# rym32g1 register map
Vendor: Rainer Yutai Meng; Series: RYM32; File version: 1
CPU: CM3 r2p1, little endian, MPU, no FPU, 4 interrupt priority bits
Registers are 32-bit, read-write, no defined reset value unless marked. A register's access mark holds for its fields unless they carry their own. Offsets are from the block's base; [hi:lo] are bit positions; {n}, {i} and the like mark numbered series.

## UART1 — Universal Synchronous Receiver Transmitter 1
Base 0x40001000
Same registers: UART2 0x40011400
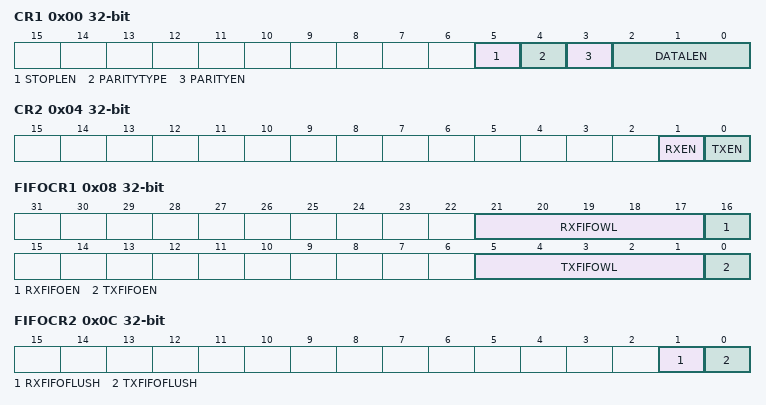
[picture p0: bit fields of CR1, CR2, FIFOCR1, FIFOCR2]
0x00 CR1 — UART1 Control Register 1
  [5] STOPLEN — UART1 CR1 STOPLEN Bit: Select stop bit(s) length
  [4] PARITYTYPE — UART1 CR1 PARITYTYPE Bit: Select parity type
  [3] PARITYEN — UART1 CR1 PARITYEN Bit: Enable / Disable parity bit
  [2:0] DATALEN — UART1 CR1 DATALEN [2:0] Bits: Select data bit(s) length
0x04 CR2 — UART1 Control Register 2
  [1] RXEN — UART1 CR2 RXEN Bit: Enable / Disable RX sub-system
  [0] TXEN — UART1 CR2 TXEN Bit: Enable / Disable TX sub-system
0x08 FIFOCR1 — UART1 FIFO Control Register 1
  [21:17] RXFIFOWL — UART1 FIFOCR1 RXFIFOWL [4:0] Bits: Select RXFIFO waterline
  [16] RXFIFOEN — UART1 FIFOCR1 RXFIFOEN Bit: Enable / Disable RXFIFO
  [5:1] TXFIFOWL — UART1 FIFOCR1 TXFIFOWL [4:0] Bits: Select TXFIFO waterline
  [0] TXFIFOEN — UART1 FIFOCR1 TXFIFOEN Bit: Enable / Disable TXFIFO
0x0C FIFOCR2 wo — UART1 FIFO Control Register 2
  [1] RXFIFOFLUSH — UART1 FIFOCR2 RXFIFOFLUSH Bit: Flush RXFIFO
  [0] TXFIFOFLUSH — UART1 FIFOCR2 TXFIFOFLUSH Bit: Flush TXFIFO
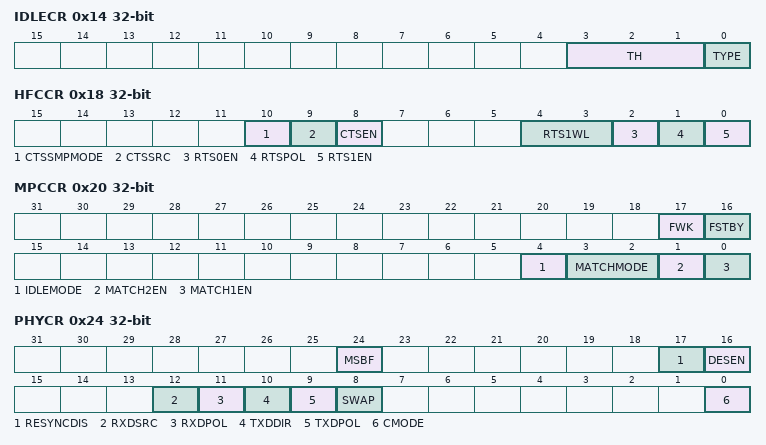
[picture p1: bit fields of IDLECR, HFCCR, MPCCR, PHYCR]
0x14 IDLECR — UART1 Idle Detection Control Register
  [3:1] TH — UART1 IDLECR TH [2:0] Bits: Select IDLE detection threshold
  [0] TYPE — UART1 IDLECR TYPE Bit: Select IDLE detection type
0x18 HFCCR — UART1 Hardware Flow Control Register
  [10] CTSSMPMODE — UART1 HFCCR CTSSMPMODE Bit: Select CTS sampling mode
  [9] CTSSRC — UART1 HFCCR CTSSRC Bit: Select CTS source (1 = align with RX standby state)
  [8] CTSEN — UART1 HFCCR CTSEN Bit: Enable / Disable CTS
  [4:3] RTS1WL — UART1 HFCCR RTS1WL [1:0] Bits: Select RTS mode1 (RX) waterline
  [2] RTS0EN — UART1 HFCCR RTS0EN Bit: Enable / Disable RTS mode0 (TX)
  [1] RTSPOL — UART1 HFCCR RTSPOL Bit: Select RTS polarity
  [0] RTS1EN — UART1 HFCCR RTS1EN Bit: Enable / Disable RTS mode1 (RX)
0x1C LINCR — UART1 LIN Control Register
  [0] BRKDETEN — UART1 LINCR BRKDETEN Bit: Enable / Disable LIN break Detection
0x20 MPCCR — UART1 Multi Processor Control Register
  [17] FWK wo — UART1 MPCCR FWK Bit: Force wake up
  [16] FSTBY wo — UART1 MPCCR FSTBY Bit: Force standby
  [4] IDLEMODE — UART1 MPCCR IDLEMODE Bit: Select IDLE flag setting on standby wakeup (MATCHMODE=00)
  [3:2] MATCHMODE — UART1 MPCCR MATCHMODE [1:0] Bits: Select match mode
  [1] MATCH2EN — UART1 MPCCR MATCH2EN Bit: Enable / Disable match buffer 2
  [0] MATCH1EN — UART1 MPCCR MATCH1EN Bit: Enable / Disable match buffer 1
0x24 PHYCR — UART1 Physical Layer Control Register
  [24] MSBF — UART1 PHYCR MSBF Bit: Enable / Disable most significant bit first mode
  [17] RESYNCDIS — UART1 PHYCR RESYNCDIS Bit: Disable / Enable resynchronization
  [16] DESEN — UART1 PHYCR DESEN Bit: Enable / Disable dual edge sampling mode
  [12] RXDSRC — UART1 PHYCR RXDSRC Bit: Select RXD source in un-full-duplex communication mode
  [11] RXDPOL — UART1 PHYCR RXDPOL Bit: Select RXD polarity
  [10] TXDDIR — UART1 PHYCR TXDDIR Bit: Select TXD direction in half-duplex mode
  [9] TXDPOL — UART1 PHYCR TXDPOL Bit: Select TXD polarity
  [8] SWAP — UART1 PHYCR SWAP Bit: Swap TXD / RXD
  [0] CMODE — UART1 PHYCR CMODE Bit: Enable / Disable un-full-duplex communication mode
0x40 BRR — UART1 Baud Rate Register
  [16:4] DIVMANT — UART1 BRR DIVMANT [12:0] Bits: Baud rate divider (mantissa)
0x44 OSRR — UART1 Oversampling Ratio Register
  [5:0] OSR — UART1 OSRR OSR [5:0] Bits: Oversampling ratio
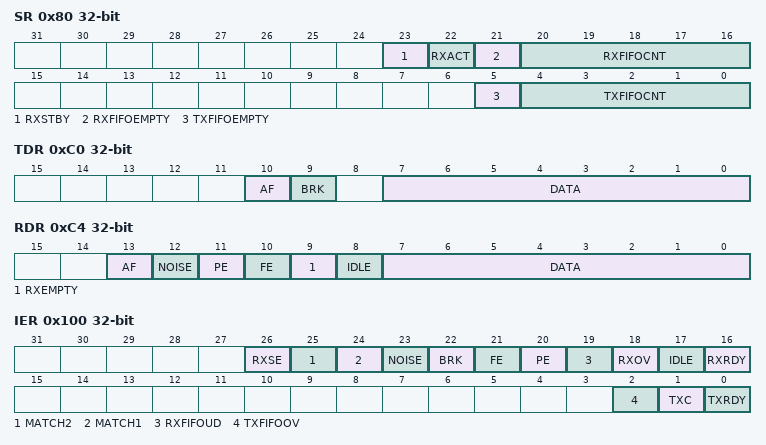
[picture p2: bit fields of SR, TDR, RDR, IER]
0x80 SR ro — UART1 Status Register
  [23] RXSTBY — UART1 SR RXSTBY Bit: RX standby
  [22] RXACT — UART1 SR RXACT Bit: RX active: valid start bit received (majority vote passed); holds until a full idle line is detected or RE=0
  [21] RXFIFOEMPTY — UART1 SR RXFIFOEMPTY Bit: RXFIFO empty
  [20:16] RXFIFOCNT — UART1 SR RXFIFOCNT [4:0] Bits: RXFIFO character count
  [5] TXFIFOEMPTY — UART1 SR TXFIFOEMPTY Bit: TXFIFO empty
  [4:0] TXFIFOCNT — UART1 SR TXFIFOCNT [4:0] Bits: TXFIFO character count
0xC0 TDR wo — UART1 TX Data Register
  [10] AF — UART1 TDR AF Bit: Transmit address frame (MATCHMODE=01/10)
  [9] BRK — UART1 TDR BRK Bit: LIN break field (fixed 13-bit low)
  [7:0] DATA — UART1 TDR DATA [7:0] Bits: Data
0xC4 RDR ro — UART1 RX Data Register
  [13] AF — UART1 RDR AF Bit: Address frame flag (MATCHMODE=01/10)
  [12] NOISE — UART1 RDR NOISE Bit: Noise in current character
  [11] PE — UART1 RDR PE Bit: Parity error in current character
  [10] FE — UART1 RDR FE Bit: Frame error in current character
  [9] RXEMPTY — UART1 RDR RXEMPTY Bit: First character after RXFIFO empty
  [8] IDLE — UART1 RDR IDLE Bit: First character after IDLE
  [7:0] DATA — UART1 RDR DATA [7:0] Bits: Data
0xC8 MDR1 — UART1 Match Data Register 1
  [7:0] DATA — UART1 MDR1 DATA [7:0] Bits: Address data for match 1
0xCC MDR2 — UART1 Match Data Register 2
  [23:16] DATA — UART1 MDR2 DATA [7:0] Bits: Address data for match 2
0x100 IER — UART1 Interrupt Enable Register
  [26] RXSE — UART1 IER RXSE Bit: Enable / Disable RX edge interrupt
  [25] MATCH2 — UART1 IER MATCH2 Bit: Enable / Disable match 2 interrupt enable
  [24] MATCH1 — UART1 IER MATCH1 Bit: Enable / Disable match 1 interrupt enable
  [23] NOISE — UART1 IER NOISE Bit: Enable / Disable noise interrupt enable
  [22] BRK — UART1 IER BRK Bit: Enable / Disable break interrupt enable
  [21] FE — UART1 IER FE Bit: Enable / Disable frame error interrupt enable
  [20] PE — UART1 IER PE Bit: Enable / Disable parity error interrupt enable
  [19] RXFIFOUD — UART1 IER RXFIFOUD Bit: Enable / Disable RXFIFO underflow interrupt
  [18] RXOV — UART1 IER RXOV Bit: Enable / Disable overrun interrupt
  [17] IDLE — UART1 IER IDLE Bit: Enable / Disable IDLE interrupt
  [16] RXRDY — UART1 IER RXRDY Bit: Enable / Disable RX interrupt
  [2] TXFIFOOV — UART1 IER TXFIFOOV Bit: Enable / Disable TXFIFO overflow interrupt
  [1] TXC — UART1 IER TXC Bit: Enable / Disable transmission complete interrupt
  [0] TXRDY — UART1 IER TXRDY Bit: Enable / Disable TX interrupt
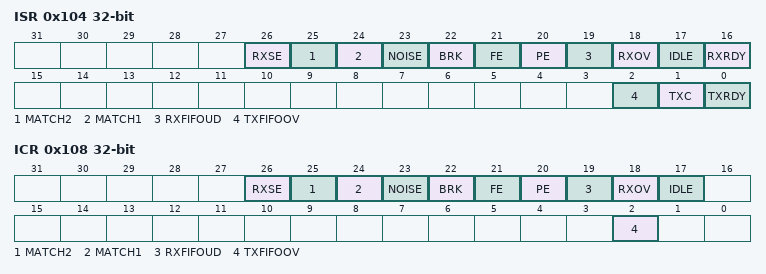
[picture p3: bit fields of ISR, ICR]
0x104 ISR ro — UART1 Interrupt Status Register
  [26] RXSE — UART1 ISR RXSE Bit: Detected falling edge on RXD (3-sample debounced; any edge, not only start edges)
  [25] MATCH2 — UART1 ISR MATCH2 Bit: Match success (match buffer 2)
  [24] MATCH1 — UART1 ISR MATCH1 Bit: Match success (match buffer 1)
  [23] NOISE — UART1 ISR NOISE Bit: Noise
  [22] BRK — UART1 ISR BRK Bit: Break
  [21] FE — UART1 ISR FE Bit: Frame error
  [20] PE — UART1 ISR PE Bit: Parity error
  [19] RXFIFOUD — UART1 ISR RXFIFOUD Bit: RXFIFO underflow
  [18] RXOV — UART1 ISR RXOV Bit: RX buffer overflow / RXFIFO overflow
  [17] IDLE — UART1 ISR IDLE Bit: IDLE
  [16] RXRDY — UART1 ISR RXRDY Bit: RX buffer empty / RXFIFO under waterline
  [2] TXFIFOOV — UART1 ISR TXFIFOOV Bit: TXFIFO overflow
  [1] TXC — UART1 ISR TXC Bit: Transmission complete
  [0] TXRDY — UART1 ISR TXRDY Bit: TX buffer full or TXFIFO over-waterline
0x108 ICR wo — UART1 Interrupt Clear Register
  [26] RXSE — UART1 ICR RXSE Bit: Clear ISR.RXSE
  [25] MATCH2 — UART1 ICR MATCH2 Bit: Clear ISR.MATCH2
  [24] MATCH1 — UART1 ICR MATCH1 Bit: Clear ISR.MATCH1
  [23] NOISE — UART1 ICR NOISE Bit: Clear ISR.NOISE
  [22] BRK — UART1 ICR BRK Bit: Clear ISR.BRK
  [21] FE — UART1 ICR FE Bit: Clear ISR.FE
  [20] PE — UART1 ICR PE Bit: Clear ISR.PE
  [19] RXFIFOUD — UART1 ICR RXFIFOUD Bit: Clear ISR.RXFIFOUD
  [18] RXOV — UART1 ICR RXOV Bit: Clear ISR.RXOV
  [17] IDLE — UART1 ICR IDLE Bit: Clear ISR.IDLE
  [2] TXFIFOOV — UART1 ICR TXFIFOOV Bit: Clear ISR.TXFIFOOV

## TUART1 — Test Universal Synchronous Receiver Transmitter 1
Base 0x40011800
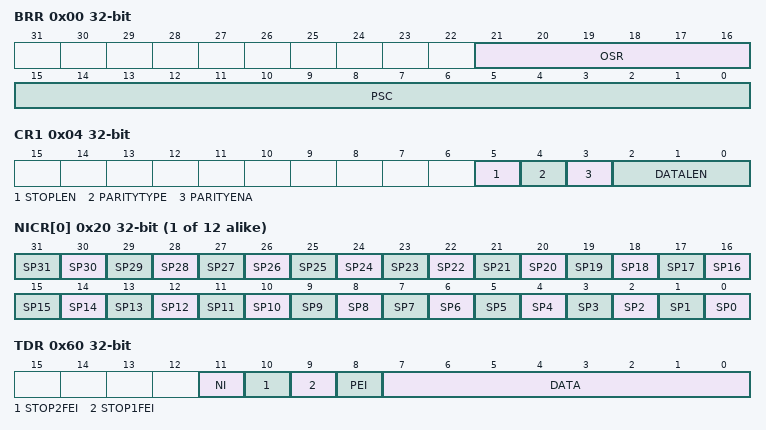
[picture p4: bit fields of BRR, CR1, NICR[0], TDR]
0x00 BRR — TUART1 Baud Rate Register
  [21:16] OSR — TUART1 BRR OSR [5:0] Bits: Oversampling Rate
  [15:0] PSC — TUART1 BRR PSC [15:0] Bits: Prescaler division factor of baud rate generator
0x04 CR1 — TUART1 Control Register 1
  [5] STOPLEN — TUART1 CR1 STOPLEN Bit: Stop bit(s) length
  [4] PARITYTYPE — TUART1 CR1 PARITYTYPE Bit: Parity type
  [3] PARITYENA — TUART1 CR1 PARITYENA Bit: Enable / Disable parity bit
  [2:0] DATALEN — TUART1 CR1 DATALEN [2:0] Bits: Data bit(s) length
0x08 CR2 — TUART1 Control Register 2
  [0] TXENA — TUART1 CR2 TXENA Bit: Enable / Disable TX sub-system
{0x20+4i} NICR[{i}] (i=0..11) — TUART1 Noise Injection Control Register X
  [n] SP{n} (n=0..31) — TUART1 NICR[%s] SP{n} Bit: Noise at sampling point {n}
0x60 TDR — TUART1 TX Data Register
  [11] NI — TUART1 TDR NI Bit: Inject noise
  [10] STOP2FEI — TUART1 TDR STOP2FEI Bit: Inject frame error at stop bit 2
  [9] STOP1FEI — TUART1 TDR STOP1FEI Bit: Inject frame error at stop bit 1
  [8] PEI — TUART1 TDR PEI Bit: Inject parity error
  [7:0] DATA — TUART1 TDR DATA [7:0] Bits: Data
0x80 SR1 ro — TUART1 Status Register 1
  [0] TXRDY — TUART1 SR1 TXRDY Bit: TX data register empty flag

## WWDG — Window Watchdog
Base 0x40000000
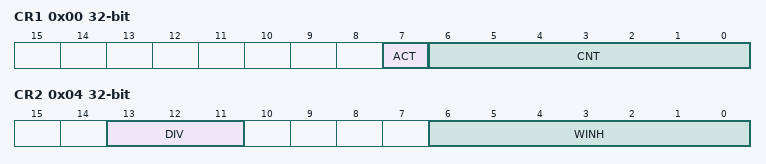
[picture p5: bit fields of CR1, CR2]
0x00 CR1 — WWDG Control Register 1
  [7] ACT — WWDG CR1 ACT Bit: Activate WWDG
  [6:0] CNT — WWDG CR1 CNT [6:0] Bits: Counter value
0x04 CR2 — WWDG Control Register 2
  [13:11] DIV — WWDG CR2 DIV [2:0] Bits: Select prescaler divider
  [6:0] WINH — WWDG CR2 WINH [6:0] Bits: Window high threshold
0x100 IER — WWDG Interrupt Enable Register
  [0] EW — WWDG IER EW Bit: Enable / Disable early wakeup interrupt
0x104 ISR ro — WWDG Interrupt Status Register
  [0] EW — WWDG ISR EW Bit: Early wakeup
0x108 ICR wo — WWDG Interrupt Clear Register
  [0] EW — WWDG ICR EW Bit: Clear ISR.EW
